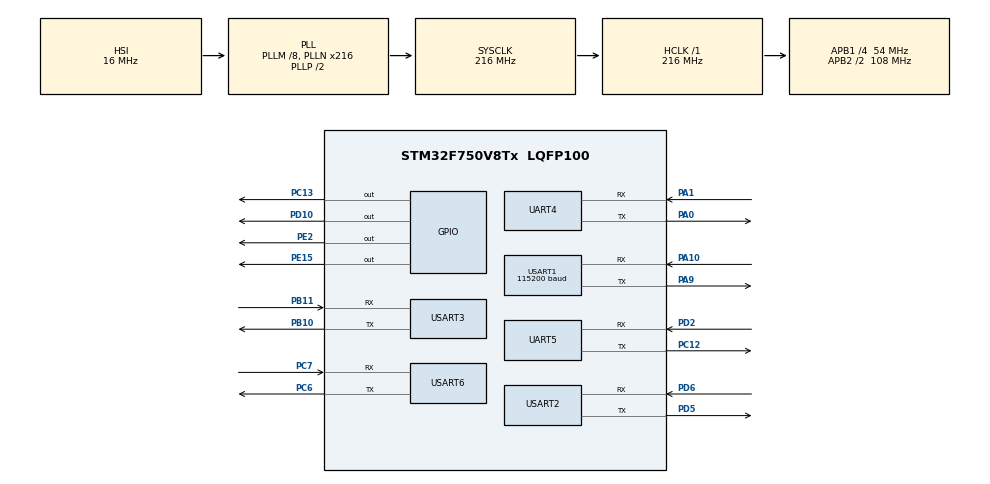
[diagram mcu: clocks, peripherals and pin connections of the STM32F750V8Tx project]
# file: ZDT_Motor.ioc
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CORTEX_M7.default_mode_Activation=1
Dma.Request0=USART3_TX
Dma.Request1=USART3_RX
Dma.Request2=UART4_RX
Dma.Request3=UART5_RX
Dma.Request4=USART6_RX
Dma.Request5=USART2_RX
Dma.Request6=USART1_RX
Dma.UART4_RX.2.Direction=DMA_PERIPH_TO_MEMORY
Dma.UART4_RX.2.FIFOMode=DMA_FIFOMODE_DISABLE
Dma.UART4_RX.2.Instance=DMA1_Stream2
Dma.UART4_RX.2.MemDataAlignment=DMA_MDATAALIGN_BYTE
Dma.UART4_RX.2.MemInc=DMA_MINC_ENABLE
Dma.UART4_RX.2.Mode=DMA_NORMAL
Dma.UART4_RX.2.PeriphDataAlignment=DMA_PDATAALIGN_BYTE
Dma.UART4_RX.2.PeriphInc=DMA_PINC_DISABLE
Dma.UART4_RX.2.Priority=DMA_PRIORITY_LOW
Dma.UART5_RX.3.Direction=DMA_PERIPH_TO_MEMORY
Dma.UART5_RX.3.FIFOMode=DMA_FIFOMODE_DISABLE
Dma.UART5_RX.3.Instance=DMA1_Stream0
Dma.UART5_RX.3.MemDataAlignment=DMA_MDATAALIGN_BYTE
Dma.UART5_RX.3.MemInc=DMA_MINC_ENABLE
Dma.UART5_RX.3.Mode=DMA_NORMAL
Dma.UART5_RX.3.PeriphDataAlignment=DMA_PDATAALIGN_BYTE
Dma.UART5_RX.3.PeriphInc=DMA_PINC_DISABLE
Dma.UART5_RX.3.Priority=DMA_PRIORITY_LOW
Dma.USART1_RX.6.Direction=DMA_PERIPH_TO_MEMORY
Dma.USART1_RX.6.FIFOMode=DMA_FIFOMODE_DISABLE
Dma.USART1_RX.6.Instance=DMA2_Stream2
Dma.USART1_RX.6.MemDataAlignment=DMA_MDATAALIGN_BYTE
Dma.USART1_RX.6.MemInc=DMA_MINC_ENABLE
Dma.USART1_RX.6.Mode=DMA_NORMAL
Dma.USART1_RX.6.PeriphDataAlignment=DMA_PDATAALIGN_BYTE
Dma.USART1_RX.6.PeriphInc=DMA_PINC_DISABLE
Dma.USART1_RX.6.Priority=DMA_PRIORITY_LOW
Dma.USART2_RX.5.Direction=DMA_PERIPH_TO_MEMORY
Dma.USART2_RX.5.FIFOMode=DMA_FIFOMODE_DISABLE
Dma.USART2_RX.5.Instance=DMA1_Stream5
Dma.USART2_RX.5.MemDataAlignment=DMA_MDATAALIGN_BYTE
Dma.USART2_RX.5.MemInc=DMA_MINC_ENABLE
Dma.USART2_RX.5.Mode=DMA_NORMAL
Dma.USART2_RX.5.PeriphDataAlignment=DMA_PDATAALIGN_BYTE
Dma.USART2_RX.5.PeriphInc=DMA_PINC_DISABLE
Dma.USART2_RX.5.Priority=DMA_PRIORITY_LOW
Dma.USART3_RX.1.Direction=DMA_PERIPH_TO_MEMORY
Dma.USART3_RX.1.FIFOMode=DMA_FIFOMODE_DISABLE
Dma.USART3_RX.1.Instance=DMA1_Stream1
Dma.USART3_RX.1.MemDataAlignment=DMA_MDATAALIGN_BYTE
Dma.USART3_RX.1.MemInc=DMA_MINC_ENABLE
Dma.USART3_RX.1.Mode=DMA_NORMAL
Dma.USART3_RX.1.PeriphDataAlignment=DMA_PDATAALIGN_BYTE
Dma.USART3_RX.1.PeriphInc=DMA_PINC_DISABLE
Dma.USART3_RX.1.Priority=DMA_PRIORITY_LOW
Dma.USART3_TX.0.Direction=DMA_MEMORY_TO_PERIPH
Dma.USART3_TX.0.FIFOMode=DMA_FIFOMODE_DISABLE
Dma.USART3_TX.0.Instance=DMA1_Stream3
Dma.USART3_TX.0.MemDataAlignment=DMA_MDATAALIGN_BYTE
Dma.USART3_TX.0.MemInc=DMA_MINC_ENABLE
Dma.USART3_TX.0.Mode=DMA_NORMAL
Dma.USART3_TX.0.PeriphDataAlignment=DMA_PDATAALIGN_BYTE
Dma.USART3_TX.0.PeriphInc=DMA_PINC_DISABLE
Dma.USART3_TX.0.Priority=DMA_PRIORITY_LOW
Dma.USART6_RX.4.Direction=DMA_PERIPH_TO_MEMORY
Dma.USART6_RX.4.FIFOMode=DMA_FIFOMODE_DISABLE
Dma.USART6_RX.4.Instance=DMA2_Stream1
Dma.USART6_RX.4.MemDataAlignment=DMA_MDATAALIGN_BYTE
Dma.USART6_RX.4.MemInc=DMA_MINC_ENABLE
Dma.USART6_RX.4.Mode=DMA_NORMAL
Dma.USART6_RX.4.PeriphDataAlignment=DMA_PDATAALIGN_BYTE
Dma.USART6_RX.4.PeriphInc=DMA_PINC_DISABLE
Dma.USART6_RX.4.Priority=DMA_PRIORITY_LOW
FREERTOS.Mutexes01=motor,Dynamic,NULL,Available
FREERTOS.Queues01=queue,16,int64_t,0,Dynamic,NULL,NULL
FREERTOS.Tasks01=Main_tasks,8,512,Main_task,Default,NULL,Dynamic,NULL,NULL;Motor_angle_get,40,512,Motor_angle_get_task,Default,NULL,Dynamic,NULL,NULL;chassis_control,40,512,chassis_control_task,Default,NULL,Dynamic,NULL,NULL
FREERTOS.configTOTAL_HEAP_SIZE=60000
Mcu.Family=STM32F7
Mcu.Name=STM32F750V8Tx
Mcu.Package=LQFP100
NVIC.DMA1_Stream0_IRQn=true\:5\:0\:false\:false\:true\:true\:false\:true\:true
NVIC.DMA1_Stream1_IRQn=true\:5\:0\:false\:false\:true\:true\:false\:true\:true
NVIC.DMA1_Stream2_IRQn=true\:5\:0\:false\:false\:true\:true\:false\:true\:true
NVIC.DMA1_Stream3_IRQn=true\:5\:0\:false\:false\:true\:true\:false\:true\:true
NVIC.DMA1_Stream5_IRQn=true\:5\:0\:false\:false\:true\:true\:false\:true\:true
NVIC.DMA2_Stream1_IRQn=true\:5\:0\:false\:false\:true\:true\:false\:true\:true
NVIC.DMA2_Stream2_IRQn=true\:5\:0\:false\:false\:true\:true\:false\:true\:true
NVIC.PriorityGroup=NVIC_PRIORITYGROUP_4
NVIC.TIM1_UP_TIM10_IRQn=true\:5\:0\:false\:false\:true\:true\:true\:true\:true
NVIC.TIM2_IRQn=true\:15\:0\:false\:false\:true\:false\:false\:true\:true
NVIC.TimeBase=TIM2_IRQn
NVIC.TimeBaseIP=TIM2
NVIC.UART4_IRQn=true\:5\:0\:false\:false\:true\:true\:true\:true\:true
NVIC.UART5_IRQn=true\:5\:0\:false\:false\:true\:true\:true\:true\:true
NVIC.USART1_IRQn=true\:5\:0\:false\:false\:true\:true\:true\:true\:true
NVIC.USART2_IRQn=true\:5\:0\:false\:false\:true\:true\:true\:true\:true
NVIC.USART3_IRQn=true\:5\:0\:false\:false\:true\:true\:true\:true\:true
NVIC.USART6_IRQn=true\:5\:0\:false\:false\:true\:true\:true\:true\:true
PA0/WKUP.Mode=Asynchronous
PA0/WKUP.Signal=UART4_TX
PA1.Mode=Asynchronous
PA1.Signal=UART4_RX
PA10.Mode=Asynchronous
PA10.Signal=USART1_RX
PA13.Mode=Serial_Wire
PA13.Signal=SYS_JTMS-SWDIO
PA14.Mode=Serial_Wire
PA14.Signal=SYS_JTCK-SWCLK
PA9.Mode=Asynchronous
PA9.Signal=USART1_TX
PB10.Mode=Asynchronous
PB10.Signal=USART3_TX
PB11.Mode=Asynchronous
PB11.Signal=USART3_RX
PC12.Mode=Asynchronous
PC12.Signal=UART5_TX
PC13.Signal=GPIO_Output
PC14/OSC32_IN.Mode=LSE-External-Oscillator
PC14/OSC32_IN.Signal=RCC_OSC32_IN
PC15/OSC32_OUT.Mode=LSE-External-Oscillator
PC15/OSC32_OUT.Signal=RCC_OSC32_OUT
PC6.Mode=Asynchronous
PC6.Signal=USART6_TX
PC7.Mode=Asynchronous
PC7.Signal=USART6_RX
PD10.Signal=GPIO_Output
PD2.Mode=Asynchronous
PD2.Signal=UART5_RX
PD5.Mode=Asynchronous
PD5.Signal=USART2_TX
PD6.Mode=Asynchronous
PD6.Signal=USART2_RX
PE15.GPIO_Speed=GPIO_SPEED_FREQ_VERY_HIGH
PE15.PinState=GPIO_PIN_RESET
PE15.Signal=GPIO_Output
PE2.Signal=GPIO_Output
PH0/OSC_IN.Mode=HSE-External-Oscillator
PH0/OSC_IN.Signal=RCC_OSC_IN
PH1/OSC_OUT.Mode=HSE-External-Oscillator
PH1/OSC_OUT.Signal=RCC_OSC_OUT
ProjectManager.HeapSize=0x200
ProjectManager.StackSize=0x400
ProjectManager.TargetToolchain=MDK-ARM V5.32
RCC.AHBFreq_Value=216000000
RCC.APB1CLKDivider=RCC_HCLK_DIV4
RCC.APB1Freq_Value=54000000
RCC.APB1TimFreq_Value=108000000
RCC.APB2CLKDivider=RCC_HCLK_DIV2
RCC.APB2Freq_Value=108000000
RCC.APB2TimFreq_Value=216000000
RCC.CortexFreq_Value=216000000
RCC.HCLKFreq_Value=216000000
RCC.HSE_VALUE=25000000
RCC.HSI_VALUE=16000000
RCC.PLLM=8
RCC.PLLN=216
RCC.SYSCLKFreq_VALUE=216000000
RCC.SYSCLKSource=RCC_SYSCLKSOURCE_PLLCLK
RCC.USBFreq_Value=216000000
RCC.VCOOutputFreq_Value=432000000
TIM1.Period=10000-1
TIM1.Prescaler=216-1
USART1.BaudRate=115200
USART1.VirtualMode-Asynchronous=VM_ASYNC
USART2.VirtualMode-Asynchronous=VM_ASYNC
USART3.VirtualMode-Asynchronous=VM_ASYNC
USART6.VirtualMode=VM_ASYNC
VP_FREERTOS_VS_CMSIS_V2.Mode=CMSIS_V2
VP_SYS_VS_tim2.Mode=TIM2
VP_TIM1_VS_ClockSourceINT.Mode=Internal
board=custom

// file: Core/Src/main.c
/* USER CODE BEGIN Header */
/**
  ******************************************************************************
  * @file           : main.c
  * @brief          : Main program body
  ******************************************************************************
  * @attention
  *
  * Copyright (c) 2026 STMicroelectronics.
  * All rights reserved.
  *
  * This software is licensed under terms that can be found in the LICENSE file
  * in the root directory of this software component.
  * If no LICENSE file comes with this software, it is provided AS-IS.
  *
  ******************************************************************************
  */
/* USER CODE END Header */
#include "main.h"
#include "cmsis_os.h"
#include "dma.h"
#include "tim.h"
#include "usart.h"
#include "gpio.h"

void SystemClock_Config(void);
static void MPU_Config(void);
void MX_FREERTOS_Init(void);

int main(void)
{

  /* MPU Configuration--------------------------------------------------------*/
  MPU_Config();

  /* MCU Configuration--------------------------------------------------------*/

  /* Reset of all peripherals, Initializes the Flash interface and the Systick. */
  HAL_Init();

  /* Configure the system clock */
  SystemClock_Config();

  /* Initialize all configured peripherals */
  MX_GPIO_Init();
  MX_DMA_Init();
  MX_USART3_UART_Init();
  MX_TIM1_Init();
  MX_UART4_Init();
  MX_UART5_Init();
  MX_USART1_UART_Init();
  MX_USART6_UART_Init();
  MX_USART2_UART_Init();

  /* Init scheduler */
  osKernelInitialize();  /* Call init function for freertos objects (in cmsis_os2.c) */
  MX_FREERTOS_Init();

  /* Start scheduler */
  osKernelStart();

  /* We should never get here as control is now taken by the scheduler */

  /* Infinite loop */
  while (1)
  {

  }
}

void SystemClock_Config(void)
{
  RCC_OscInitTypeDef RCC_OscInitStruct = {0};
  RCC_ClkInitTypeDef RCC_ClkInitStruct = {0};

  /** Configure LSE Drive Capability
  */
  HAL_PWR_EnableBkUpAccess();

  /** Configure the main internal regulator output voltage
  */
  __HAL_RCC_PWR_CLK_ENABLE();
  __HAL_PWR_VOLTAGESCALING_CONFIG(PWR_REGULATOR_VOLTAGE_SCALE1);

  /** Initializes the RCC Oscillators according to the specified parameters
  * in the RCC_OscInitTypeDef structure.
  */
  RCC_OscInitStruct.OscillatorType = RCC_OSCILLATORTYPE_HSI;
  RCC_OscInitStruct.HSIState = RCC_HSI_ON;
  RCC_OscInitStruct.HSICalibrationValue = RCC_HSICALIBRATION_DEFAULT;
  RCC_OscInitStruct.PLL.PLLState = RCC_PLL_ON;
  RCC_OscInitStruct.PLL.PLLSource = RCC_PLLSOURCE_HSI;
  RCC_OscInitStruct.PLL.PLLM = 8;
  RCC_OscInitStruct.PLL.PLLN = 216;
  RCC_OscInitStruct.PLL.PLLP = RCC_PLLP_DIV2;
  RCC_OscInitStruct.PLL.PLLQ = 2;
  if (HAL_RCC_OscConfig(&RCC_OscInitStruct) != HAL_OK)
  {
    Error_Handler();
  }

  /** Activate the Over-Drive mode
  */
  if (HAL_PWREx_EnableOverDrive() != HAL_OK)
  {
    Error_Handler();
  }

  /** Initializes the CPU, AHB and APB buses clocks
  */
  RCC_ClkInitStruct.ClockType = RCC_CLOCKTYPE_HCLK|RCC_CLOCKTYPE_SYSCLK
                              |RCC_CLOCKTYPE_PCLK1|RCC_CLOCKTYPE_PCLK2;
  RCC_ClkInitStruct.SYSCLKSource = RCC_SYSCLKSOURCE_PLLCLK;
  RCC_ClkInitStruct.AHBCLKDivider = RCC_SYSCLK_DIV1;
  RCC_ClkInitStruct.APB1CLKDivider = RCC_HCLK_DIV4;
  RCC_ClkInitStruct.APB2CLKDivider = RCC_HCLK_DIV2;

  if (HAL_RCC_ClockConfig(&RCC_ClkInitStruct, FLASH_LATENCY_7) != HAL_OK)
  {
    Error_Handler();
  }
}

 /* MPU Configuration */

void MPU_Config(void)
{
  MPU_Region_InitTypeDef MPU_InitStruct = {0};

  /* Disables the MPU */
  HAL_MPU_Disable();

  /** Initializes and configures the Region and the memory to be protected
  */
  MPU_InitStruct.Enable = MPU_REGION_ENABLE;
  MPU_InitStruct.Number = MPU_REGION_NUMBER0;
  MPU_InitStruct.BaseAddress = 0x0;
  MPU_InitStruct.Size = MPU_REGION_SIZE_4GB;
  MPU_InitStruct.SubRegionDisable = 0x87;
  MPU_InitStruct.TypeExtField = MPU_TEX_LEVEL0;
  MPU_InitStruct.AccessPermission = MPU_REGION_NO_ACCESS;
  MPU_InitStruct.DisableExec = MPU_INSTRUCTION_ACCESS_DISABLE;
  MPU_InitStruct.IsShareable = MPU_ACCESS_SHAREABLE;
  MPU_InitStruct.IsCacheable = MPU_ACCESS_NOT_CACHEABLE;
  MPU_InitStruct.IsBufferable = MPU_ACCESS_NOT_BUFFERABLE;

  HAL_MPU_ConfigRegion(&MPU_InitStruct);
  /* Enables the MPU */
  HAL_MPU_Enable(MPU_PRIVILEGED_DEFAULT);

}

void HAL_TIM_PeriodElapsedCallback(TIM_HandleTypeDef *htim)
{
  if (htim->Instance == TIM2)
  {
    HAL_IncTick();
  }
}

void Error_Handler(void)
{
  __disable_irq();
  while (1)
  {
  }
}

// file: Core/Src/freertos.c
/* USER CODE BEGIN Header */
/**
  ******************************************************************************
  * File Name          : freertos.c
  * Description        : Code for freertos applications
  ******************************************************************************
  * @attention
  *
  * Copyright (c) 2026 STMicroelectronics.
  * All rights reserved.
  *
  * This software is licensed under terms that can be found in the LICENSE file
  * in the root directory of this software component.
  * If no LICENSE file comes with this software, it is provided AS-IS.
  *
  ******************************************************************************
  */
/* USER CODE END Header */

#include "FreeRTOS.h"
#include "task.h"
#include "main.h"
#include "cmsis_os.h"

/* USER CODE BEGIN Includes */
#include "app_main.h"

#include "usart.h"
/* USER CODE END Includes */

/* Definitions for Main_tasks */
osThreadId_t Main_tasksHandle;
const osThreadAttr_t Main_tasks_attributes = {
  .name = "Main_tasks",
  .stack_size = 512 * 4,
  .priority = (osPriority_t) osPriorityLow,
};
/* Definitions for Motor_angle_get */
osThreadId_t Motor_angle_getHandle;
const osThreadAttr_t Motor_angle_get_attributes = {
  .name = "Motor_angle_get",
  .stack_size = 512 * 4,
  .priority = (osPriority_t) osPriorityHigh,
};
/* Definitions for chassis_control */
osThreadId_t chassis_controlHandle;
const osThreadAttr_t chassis_control_attributes = {
  .name = "chassis_control",
  .stack_size = 512 * 4,
  .priority = (osPriority_t) osPriorityHigh,
};
/* Definitions for queue */
osMessageQueueId_t queueHandle;
const osMessageQueueAttr_t queue_attributes = {
  .name = "queue"
};
/* Definitions for motor */
osMutexId_t motorHandle;
const osMutexAttr_t motor_attributes = {
  .name = "motor"
};

void Main_task(void *argument);
void Motor_angle_get_task(void *argument);
void chassis_control_task(void *argument);

void MX_FREERTOS_Init(void); /* (MISRA C 2004 rule 8.1) */

void MX_FREERTOS_Init(void) {
  /* Create the mutex(es) */
  /* creation of motor */
  motorHandle = osMutexNew(&motor_attributes);

  /* Create the queue(s) */
  /* creation of queue */
  queueHandle = osMessageQueueNew (16, sizeof(int64_t), &queue_attributes);

  /* Create the thread(s) */
  /* creation of Main_tasks */
  Main_tasksHandle = osThreadNew(Main_task, NULL, &Main_tasks_attributes);

  /* creation of Motor_angle_get */
  Motor_angle_getHandle = osThreadNew(Motor_angle_get_task, NULL, &Motor_angle_get_attributes);

  /* creation of chassis_control */
  chassis_controlHandle = osThreadNew(chassis_control_task, NULL, &chassis_control_attributes);

}

void Main_task(void *argument)
{
  /* USER CODE BEGIN Main_task */
  /* 调度器已运行，组装并启动各子系统（电机 + 陀螺仪），仅一次 */
  uint8_t cmd[5] = {0xFF, 0xAA, 0x69, 0x88, 0xB5};
	HAL_UART_Transmit(&huart2, cmd, 5,100);
	osDelay(210);
	cmd[2] = 0x76;
	cmd[3] = 0x00;
	cmd[4] = 0x00;
	HAL_UART_Transmit(&huart2, cmd, 5,100);
	cmd[2] = 0x00;
	osDelay(510);
	HAL_UART_Transmit(&huart2, cmd, 5,100);
  (void)app_init();
  /* Infinite loop */
  for(;;)
  {
    osDelay(1);
  }
  /* USER CODE END Main_task */
}

void Motor_angle_get_task(void *argument)
{
  for(;;)
  {
    osDelay(1);
  }
}

void chassis_control_task(void *argument)
{
  for(;;)
  {
    osDelay(1);
  }
}
